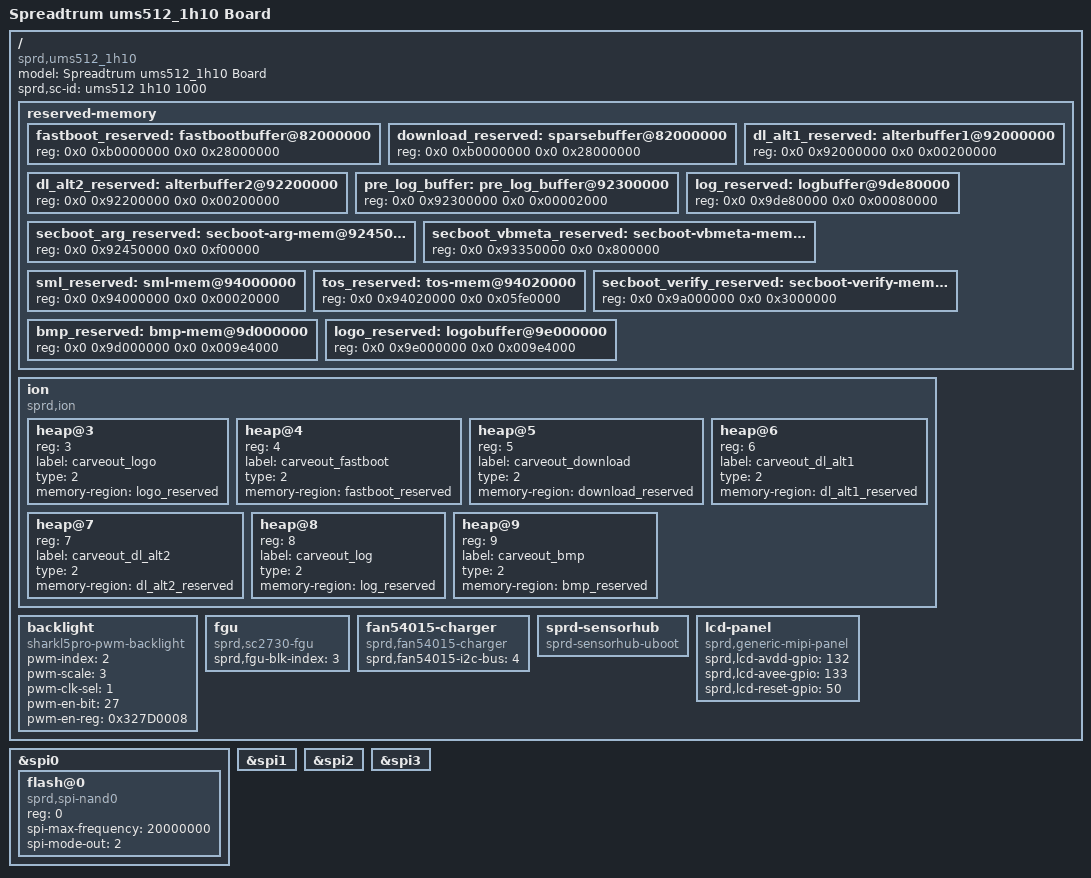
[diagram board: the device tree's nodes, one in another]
/*
 * Spreadtrum SP9860g board DTS file
 *
 * Copyright (C) 2016, Spreadtrum Communications Inc.
 *
 * This file is licensed under a dual GPLv2 or X11 license.
 */

/dts-v1/;

#include "ums512.dtsi"
#include "sc2730.dtsi"
#include "lcd/lcd_td4310_truly_mipi_fhd.dtsi"
#include "lcd/lcd_ssd2092_truly_mipi_fhd.dtsi"
#include "lcd/lcd_ssd2092_truly_mipi_fhd_v2.dtsi"
#include "lcd/lcd_dummy_mipi.dtsi"

/ {
	model = "Spreadtrum ums512_1h10 Board";

	compatible = "sprd,ums512_1h10";

	sprd,sc-id = "ums512 1h10 1000";

	reserved-memory {
		#address-cells = <2>;
		#size-cells = <2>;
		ranges;

		fastboot_reserved: fastbootbuffer@82000000{
			reg = <0x0 0xb0000000 0x0 0x28000000>;
		};

		download_reserved: sparsebuffer@82000000{
			reg = <0x0 0xb0000000 0x0 0x28000000>;
		};

		dl_alt1_reserved: alterbuffer1@92000000{
			reg = <0x0 0x92000000 0x0 0x00200000>;
		};

		dl_alt2_reserved: alterbuffer2@92200000{
			reg = <0x0 0x92200000 0x0 0x00200000>;
		};

		pre_log_buffer: pre_log_buffer@92300000{
			reg = <0x0 0x92300000 0x0 0x00002000>;
		};

		log_reserved: logbuffer@9de80000{
			reg = <0x0 0x9de80000 0x0 0x00080000>;
		};

		secboot_arg_reserved: secboot-arg-mem@92450000{
			reg = <0x0 0x92450000 0x0 0xf00000>;
		};

		secboot_vbmeta_reserved: secboot-vbmeta-mem@93350000{
			reg = <0x0 0x93350000 0x0 0x800000>;
		};

		/* must be 4K aligned */
		sml_reserved: sml-mem@94000000{
			reg = <0x0 0x94000000 0x0 0x00020000>;
		};

		tos_reserved: tos-mem@94020000{
			reg = <0x0 0x94020000 0x0 0x05fe0000>;
		};

		secboot_verify_reserved: secboot-verify-mem@0x9a000000{
			reg = <0x0 0x9a000000 0x0 0x3000000>;
		};

		bmp_reserved: bmp-mem@9d000000 {
			reg = <0x0 0x9d000000 0x0 0x009e4000>;
		};

		/* 1080x2400x4Bytes & 4K alignment*/
		logo_reserved: logobuffer@9e000000{
			reg = <0x0 0x9e000000 0x0 0x009e4000>;
		};
	};

	ion {
		compatible = "sprd,ion";
		#address-cells = <1>;
		#size-cells = <0>;

		heap@3 {
			reg = <3>;
			label = "carveout_logo";
			type = <2>;
			memory-region = <&logo_reserved>;
		};

		heap@4 {
			reg = <4>;
			label = "carveout_fastboot";
			type = <2>;
			memory-region = <&fastboot_reserved>;
		};

		heap@5 {
			reg = <5>;
			label = "carveout_download";
			type = <2>;
			memory-region = <&download_reserved>;
		};

		heap@6 {
			reg = <6>;
			label = "carveout_dl_alt1";
			type = <2>;
			memory-region = <&dl_alt1_reserved>;
		};

		heap@7 {
			reg = <7>;
			label = "carveout_dl_alt2";
			type = <2>;
			memory-region = <&dl_alt2_reserved>;
		};

		heap@8 {
			reg = <8>;
			label = "carveout_log";
			type = <2>;
			memory-region = <&log_reserved>;
		};

		heap@9 {
			reg = <9>;
			label = "carveout_bmp";
			type = <2>;
			memory-region = <&bmp_reserved>;
		};
	};

	backlight {
		compatible = "sharkl5pro-pwm-backlight";
		pwm-index = <2>;
		pwm-scale = <3>;
		pwm-clk-sel = <1>;
		pwm-en-bit = <27>;
		pwm-en-reg = <0x327D0008>;
	};

	fgu {
		/*sc2721 sc2731 sc2720 sc2730:the same
		 *ums512-1h10 use sc2730
		 *this para must config carefully,or can't power on
		 */
		compatible = "sprd,sc2730-fgu";
		sprd,fgu-blk-index = <3>;
	};

	fan54015-charger {
		compatible = "sprd,fan54015-charger";
		sprd,fan54015-i2c-bus = <4>;
	};

	sprd-sensorhub {
		compatible = "sprd-sensorhub-uboot";
	};

	lcd-panel {
		compatible = "sprd,generic-mipi-panel";
		sprd,lcd-avdd-gpio = <132>;
		sprd,lcd-avee-gpio = <133>;
		sprd,lcd-reset-gpio = <50>;
	};
};

&spi0 {
	status = "okay";
	flash@0 {//this just for example
		#address-cells = <1>;
		#size-cells = <0>;
		compatible = "sprd,spi-nand0";
		reg = <0>;
		spi-max-frequency = <20000000>;
		spi-mode-out = <2>;
	};
};
&spi1 {
	status = "okay";
};
&spi2 {
	status = "okay";
};
&spi3 {
	status = "okay";
};
